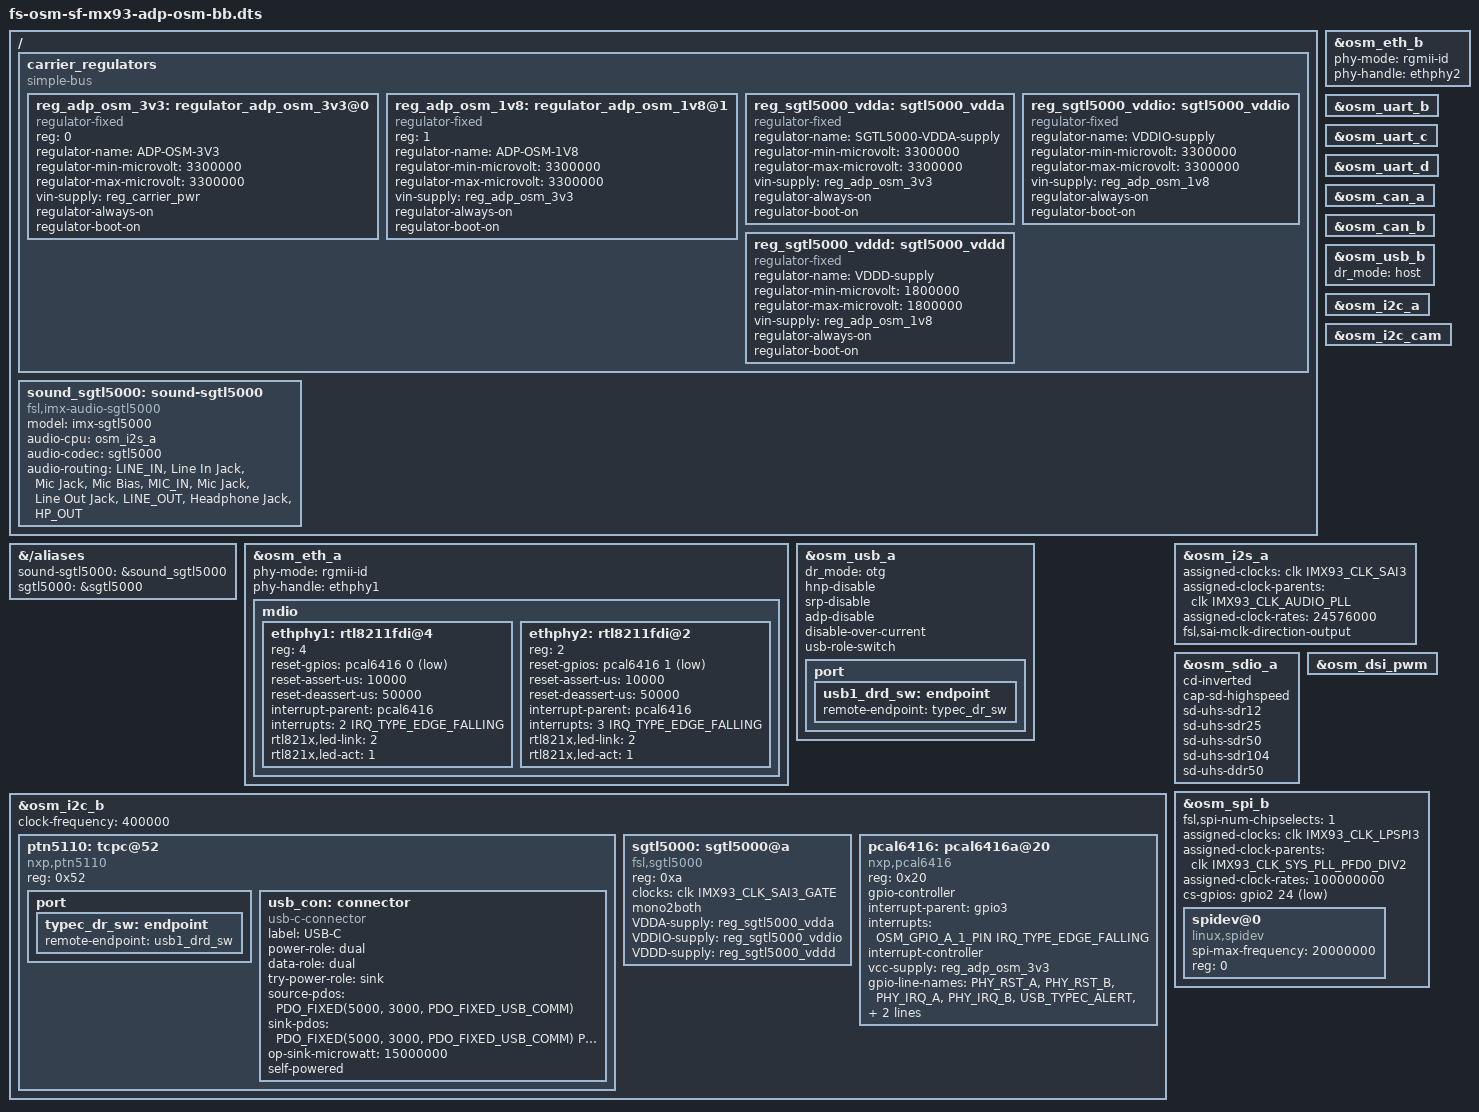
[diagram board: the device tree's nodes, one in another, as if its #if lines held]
// SPDX-License-Identifier: GPL-2.0
/*
* Copyright 2024 F&S Elektronik Systeme GmbH
*
* This program is free software; you can redistribute it and/or modify
* it under the terms of the GNU General Public License version 2 as
* published by the Free Software Foundation.
*
* This program is distributed in the hope that it will be useful,
* but WITHOUT ANY WARRANTY; without even the implied warranty of
* MERCHANTABILITY or FITNESS FOR A PARTICULAR PURPOSE.  See the
* GNU General Public License for more details.
*/

/* When Undefined, IO of UARTC and UARTD will be configured as GPIO */
// #define CONFIG_OSMSFMX93_UARTC
// #define CONFIG_OSMSFMX93_UARTD

/* Enable to use CM33 and RPMSG */
// #define SUPPORT_M33
// #define SUPPORT_RPMSG

#define ADP_OSM_BB_REV 130

#include "fs-osm-sf-mx93.dtsi"
#include <dt-bindings/usb/pd.h>

&{/aliases} {
	sound-sgtl5000 = &sound_sgtl5000;
	sgtl5000 = &sgtl5000;
};

/ {
	carrier_regulators{
		compatible = "simple-bus";
		#address-cells = <1>;
		#size-cells = <0>;

		reg_adp_osm_3v3: regulator_adp_osm_3v3@0 {
			compatible = "regulator-fixed";
			reg = <0>;
			regulator-name = "ADP-OSM-3V3";
			regulator-min-microvolt = <3300000>;
			regulator-max-microvolt = <3300000>;
			vin-supply = <&reg_carrier_pwr>;
			regulator-always-on;
			regulator-boot-on;
		};

		reg_adp_osm_1v8: regulator_adp_osm_1v8@1 {
			compatible = "regulator-fixed";
			reg = <1>;
			regulator-name = "ADP-OSM-1V8";
			regulator-min-microvolt = <3300000>;
			regulator-max-microvolt = <3300000>;
			vin-supply = <&reg_adp_osm_3v3>;
			regulator-always-on;
			regulator-boot-on;
		};

		/* SGTL5000 analog voltage */
		reg_sgtl5000_vdda: sgtl5000_vdda {
			compatible = "regulator-fixed";
			regulator-name = "SGTL5000-VDDA-supply";
			regulator-min-microvolt = <3300000>;
			regulator-max-microvolt = <3300000>;
			vin-supply = <&reg_adp_osm_3v3>;
			regulator-always-on;
			regulator-boot-on;
		};

		/* SGTL5000 I/O voltage */
		reg_sgtl5000_vddio: sgtl5000_vddio {
			compatible = "regulator-fixed";
			regulator-name = "VDDIO-supply";
			regulator-min-microvolt = <3300000>;
			regulator-max-microvolt = <3300000>;
			vin-supply = <&reg_adp_osm_1v8>;
			regulator-always-on;
			regulator-boot-on;
		};

		/* SGTL5000 internal digital voltage */
		reg_sgtl5000_vddd: sgtl5000_vddd {
			compatible = "regulator-fixed";
			regulator-name = "VDDD-supply";
			regulator-min-microvolt = <1800000>;
			regulator-max-microvolt = <1800000>;
			vin-supply = <&reg_adp_osm_1v8>;
			regulator-always-on;
			regulator-boot-on;
		};
	};

	sound_sgtl5000: sound-sgtl5000 {
		compatible = "fsl,imx-audio-sgtl5000";
		model = "imx-sgtl5000";
		audio-cpu = <&osm_i2s_a>;
		audio-codec = <&sgtl5000>;
		audio-routing =
			"LINE_IN", "Line In Jack",
			"Mic Jack", "Mic Bias",
			"MIC_IN", "Mic Jack",
			"Line Out Jack", "LINE_OUT",
			"Headphone Jack", "HP_OUT";
	};
};

&osm_eth_a {
	phy-mode = "rgmii-id";
	phy-handle = <&ethphy1>;
	status = "okay";
#if ADP_OSM_BB_REV == 130
	mdio {
		status = "okay";
		ethphy1: rtl8211fdi@4 {
			reg = <4>;
			reset-gpios = <&pcal6416 0 GPIO_ACTIVE_LOW>;
			reset-assert-us = <10000>;
			reset-deassert-us = <50000>;
			interrupt-parent = <&pcal6416>;
			interrupts = <2 IRQ_TYPE_EDGE_FALLING>;
			rtl821x,led-link = <2>; // LED2 for link indication
			rtl821x,led-act = <1>; // LED1 for activity
		};

		ethphy2: rtl8211fdi@2 {
			reg = <2>;
			reset-gpios = <&pcal6416 1 GPIO_ACTIVE_LOW>;
			reset-assert-us = <10000>;
			reset-deassert-us = <50000>;
			interrupt-parent = <&pcal6416>;
			interrupts = <3 IRQ_TYPE_EDGE_FALLING>;
			rtl821x,led-link = <2>; // LED2 for link indication
			rtl821x,led-act = <1>; // LED1 for activity
		};
	};
#else
	mdio {
		status = "okay";
		ethphy1: rtl8211fdi@4 {
			reg = <4>;
			rtl821x,led-link = <2>; // LED2 for link indication
			rtl821x,led-act = <1>; // LED1 for activity
		};

		ethphy2: rtl8211fdi@2 {
			reg = <2>;
			rtl821x,led-link = <2>; // LED2 for link indication
			rtl821x,led-act = <1>; // LED1 for activity
		};
	};
#endif
};

&osm_eth_b {
	phy-mode = "rgmii-id";
	phy-handle = <&ethphy2>;
	status = "okay";
};

&osm_uart_b {
	status = "okay";
};

#if defined(CONFIG_OSMSFMX93_UARTC)
&osm_uart_c {
	status = "okay";
};
#endif

#if defined(CONFIG_OSMSFMX93_UARTD)
&osm_uart_d {
	status = "okay";
};
#endif

&osm_can_a {
	status = "okay";
};

&osm_can_b {
	status = "okay";
};

&osm_usb_a {
	dr_mode = "otg";
	hnp-disable;
	srp-disable;
	adp-disable;
	disable-over-current;
	usb-role-switch;
	status = "okay";

	port {
		usb1_drd_sw: endpoint {
			remote-endpoint = <&typec_dr_sw>;
		};
	};
};

&osm_usb_b {
	dr_mode = "host";
	status = "okay";
};

&osm_i2c_a {
	status = "okay";
};

&osm_i2c_b {
	clock-frequency = <400000>;
	status = "okay";

	ptn5110: tcpc@52 {
		compatible = "nxp,ptn5110";
		reg = <0x52>;
#if ADP_OSM_BB_REV ==  130
		/**
		 * TODO:
		 * IRQ_TRIGGER_TYPE_LOW is not supported by pcal6416.
		 * Edgle Level Support for tcpci.c will come with v6.12
		 */
		// interrupt-parent = <&pcal6416>;
		// interrupts = <4 IRQ_TYPE_EDGE_FALLING>;
#endif
		port {
			typec_dr_sw: endpoint {
				remote-endpoint = <&usb1_drd_sw>;
			};
		};

		usb_con: connector {
			compatible = "usb-c-connector";
			label = "USB-C";
			power-role = "dual";
			data-role = "dual";
			try-power-role = "sink";
			source-pdos = <PDO_FIXED(5000, 3000,
			PDO_FIXED_USB_COMM)>;
			sink-pdos = <PDO_FIXED(5000, 3000, PDO_FIXED_USB_COMM)
				     PDO_VAR(5000, 20000, 3000)>;
			op-sink-microwatt = <15000000>;
			self-powered;
		};
	};

	sgtl5000: sgtl5000@a {
		#sound-dai-cells = <0>;
		compatible = "fsl,sgtl5000";
		reg = <0xa>;
		clocks = <&clk IMX93_CLK_SAI3_GATE>;
		mono2both;
		VDDA-supply = <&reg_sgtl5000_vdda>;
		VDDIO-supply = <&reg_sgtl5000_vddio>;
		VDDD-supply = <&reg_sgtl5000_vddd>;
		status = "okay";
	};

#if ADP_OSM_BB_REV == 130
	pcal6416: pcal6416a@20 {
		compatible = "nxp,pcal6416";
		reg = <0x20>;
		gpio-controller;
		#gpio-cells = <2>;
		interrupt-parent = <&gpio3>;
		interrupts = <OSM_GPIO_A_1_PIN IRQ_TYPE_EDGE_FALLING>;
		interrupt-controller;
		#interrupt-cells = <2>;
		vcc-supply = <&reg_adp_osm_3v3>;
		gpio-line-names = 
		/* 0-4 */	"PHY_RST_A","PHY_RST_B","PHY_IRQ_A","PHY_IRQ_B","USB_TYPEC_ALERT",
		/* 5-9 */	"MIPI_RESET","TOUCH_RESET","BL_ON","VLCD_ON","GPIO_J1_44",
		/* 10-14 */	"GPIO_J1_46","","","","",
		/* 15 */	"";
	};
#endif
};

&osm_i2c_cam {
	status = "okay";
};

&osm_i2s_a {
	assigned-clocks = <&clk IMX93_CLK_SAI3>;
	assigned-clock-parents = <&clk IMX93_CLK_AUDIO_PLL>;
	assigned-clock-rates = <24576000>; //512*48kHz
	fsl,sai-mclk-direction-output;
	status = "okay";
};

&osm_sdio_a {
	cd-inverted;
	cap-sd-highspeed;
	sd-uhs-sdr12;
	sd-uhs-sdr25;
	sd-uhs-sdr50;
	sd-uhs-sdr104;
	sd-uhs-ddr50;
	status = "okay";
};

&osm_dsi_pwm {
	status = "okay";
};

&osm_spi_b {
	fsl,spi-num-chipselects = <1>;
	assigned-clocks = <&clk IMX93_CLK_LPSPI3>;
	assigned-clock-parents = <&clk IMX93_CLK_SYS_PLL_PFD0_DIV2>;
	assigned-clock-rates = <100000000>;
	cs-gpios = <&gpio2 24 GPIO_ACTIVE_LOW>;
	status = "okay";

	spidev@0 {
		compatible = "linux,spidev";
		spi-max-frequency = <20000000>;
		reg = <0>;
		status = "okay";
	};
};
